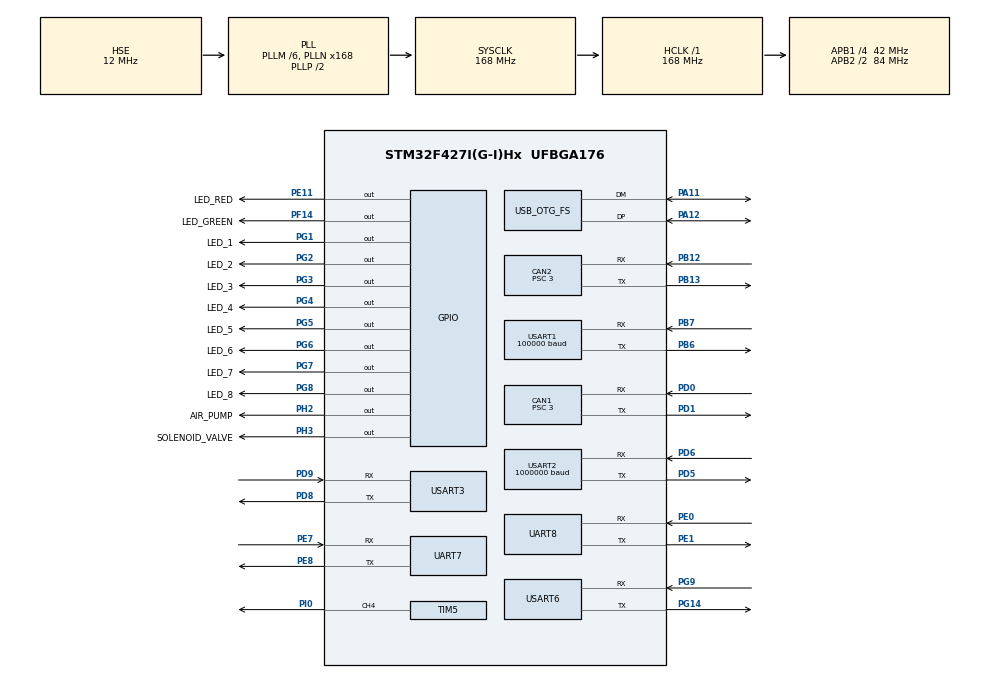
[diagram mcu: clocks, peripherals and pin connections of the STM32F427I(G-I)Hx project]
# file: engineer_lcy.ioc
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CAN1.ABOM=ENABLE
CAN1.BS1=CAN_BS1_7TQ
CAN1.BS2=CAN_BS2_6TQ
CAN1.CalculateBaudRate=1000000
CAN1.CalculateTimeBit=1000
CAN1.CalculateTimeQuantum=71.42857142857143
CAN1.Prescaler=3
CAN2.ABOM=ENABLE
CAN2.BS1=CAN_BS1_7TQ
CAN2.BS2=CAN_BS2_6TQ
CAN2.CalculateBaudRate=1000000
CAN2.CalculateTimeBit=1000
CAN2.CalculateTimeQuantum=71.42857142857143
CAN2.Prescaler=3
Dma.Request0=UART7_RX
Dma.Request1=UART8_RX
Dma.Request2=USART6_RX
Dma.Request3=USART3_RX
Dma.Request4=USART1_RX
Dma.Request5=USART2_RX
Dma.UART7_RX.0.Direction=DMA_PERIPH_TO_MEMORY
Dma.UART7_RX.0.FIFOMode=DMA_FIFOMODE_DISABLE
Dma.UART7_RX.0.Instance=DMA1_Stream3
Dma.UART7_RX.0.MemDataAlignment=DMA_MDATAALIGN_BYTE
Dma.UART7_RX.0.MemInc=DMA_MINC_ENABLE
Dma.UART7_RX.0.Mode=DMA_NORMAL
Dma.UART7_RX.0.PeriphDataAlignment=DMA_PDATAALIGN_BYTE
Dma.UART7_RX.0.PeriphInc=DMA_PINC_DISABLE
Dma.UART7_RX.0.Priority=DMA_PRIORITY_LOW
Dma.UART8_RX.1.Direction=DMA_PERIPH_TO_MEMORY
Dma.UART8_RX.1.FIFOMode=DMA_FIFOMODE_DISABLE
Dma.UART8_RX.1.Instance=DMA1_Stream6
Dma.UART8_RX.1.MemDataAlignment=DMA_MDATAALIGN_BYTE
Dma.UART8_RX.1.MemInc=DMA_MINC_ENABLE
Dma.UART8_RX.1.Mode=DMA_NORMAL
Dma.UART8_RX.1.PeriphDataAlignment=DMA_PDATAALIGN_BYTE
Dma.UART8_RX.1.PeriphInc=DMA_PINC_DISABLE
Dma.UART8_RX.1.Priority=DMA_PRIORITY_LOW
Dma.USART1_RX.4.Direction=DMA_PERIPH_TO_MEMORY
Dma.USART1_RX.4.FIFOMode=DMA_FIFOMODE_DISABLE
Dma.USART1_RX.4.Instance=DMA2_Stream2
Dma.USART1_RX.4.MemDataAlignment=DMA_MDATAALIGN_BYTE
Dma.USART1_RX.4.MemInc=DMA_MINC_ENABLE
Dma.USART1_RX.4.Mode=DMA_NORMAL
Dma.USART1_RX.4.PeriphDataAlignment=DMA_PDATAALIGN_BYTE
Dma.USART1_RX.4.PeriphInc=DMA_PINC_DISABLE
Dma.USART1_RX.4.Priority=DMA_PRIORITY_LOW
Dma.USART2_RX.5.Direction=DMA_PERIPH_TO_MEMORY
Dma.USART2_RX.5.FIFOMode=DMA_FIFOMODE_DISABLE
Dma.USART2_RX.5.Instance=DMA1_Stream5
Dma.USART2_RX.5.MemDataAlignment=DMA_MDATAALIGN_BYTE
Dma.USART2_RX.5.MemInc=DMA_MINC_ENABLE
Dma.USART2_RX.5.Mode=DMA_NORMAL
Dma.USART2_RX.5.PeriphDataAlignment=DMA_PDATAALIGN_BYTE
Dma.USART2_RX.5.PeriphInc=DMA_PINC_DISABLE
Dma.USART2_RX.5.Priority=DMA_PRIORITY_LOW
Dma.USART3_RX.3.Direction=DMA_PERIPH_TO_MEMORY
Dma.USART3_RX.3.FIFOMode=DMA_FIFOMODE_DISABLE
Dma.USART3_RX.3.Instance=DMA1_Stream1
Dma.USART3_RX.3.MemDataAlignment=DMA_MDATAALIGN_BYTE
Dma.USART3_RX.3.MemInc=DMA_MINC_ENABLE
Dma.USART3_RX.3.Mode=DMA_NORMAL
Dma.USART3_RX.3.PeriphDataAlignment=DMA_PDATAALIGN_BYTE
Dma.USART3_RX.3.PeriphInc=DMA_PINC_DISABLE
Dma.USART3_RX.3.Priority=DMA_PRIORITY_LOW
Dma.USART6_RX.2.Direction=DMA_PERIPH_TO_MEMORY
Dma.USART6_RX.2.FIFOMode=DMA_FIFOMODE_DISABLE
Dma.USART6_RX.2.Instance=DMA2_Stream1
Dma.USART6_RX.2.MemDataAlignment=DMA_MDATAALIGN_BYTE
Dma.USART6_RX.2.MemInc=DMA_MINC_ENABLE
Dma.USART6_RX.2.Mode=DMA_NORMAL
Dma.USART6_RX.2.PeriphDataAlignment=DMA_PDATAALIGN_BYTE
Dma.USART6_RX.2.PeriphInc=DMA_PINC_DISABLE
Dma.USART6_RX.2.Priority=DMA_PRIORITY_LOW
IWDG.Prescaler=IWDG_PRESCALER_32
IWDG.Reload=1023
Mcu.Family=STM32F4
Mcu.Name=STM32F427I(G-I)Hx
Mcu.Package=UFBGA176
NVIC.CAN1_RX0_IRQn=true\:0\:0\:false\:false\:true\:true\:true\:true
NVIC.CAN1_RX1_IRQn=true\:0\:0\:false\:false\:true\:true\:true\:true
NVIC.CAN2_RX0_IRQn=true\:0\:0\:false\:false\:true\:true\:true\:true
NVIC.CAN2_RX1_IRQn=true\:0\:0\:false\:false\:true\:true\:true\:true
NVIC.DMA1_Stream1_IRQn=true\:0\:0\:false\:false\:true\:false\:true\:true
NVIC.DMA1_Stream3_IRQn=true\:0\:0\:false\:false\:true\:false\:true\:true
NVIC.DMA1_Stream5_IRQn=true\:0\:0\:false\:false\:true\:false\:true\:true
NVIC.DMA1_Stream6_IRQn=true\:0\:0\:false\:false\:true\:false\:true\:true
NVIC.DMA2_Stream1_IRQn=true\:0\:0\:false\:false\:true\:false\:true\:true
NVIC.DMA2_Stream2_IRQn=true\:0\:0\:false\:false\:true\:false\:true\:true
NVIC.OTG_FS_IRQn=true\:0\:0\:false\:false\:true\:true\:true\:true
NVIC.PriorityGroup=NVIC_PRIORITYGROUP_4
NVIC.TIM6_DAC_IRQn=true\:0\:0\:false\:false\:true\:true\:true\:true
NVIC.UART7_IRQn=true\:0\:0\:false\:false\:true\:true\:true\:true
NVIC.UART8_IRQn=true\:0\:0\:false\:false\:true\:true\:true\:true
NVIC.USART1_IRQn=true\:0\:0\:false\:false\:true\:true\:true\:true
NVIC.USART2_IRQn=true\:0\:0\:false\:false\:true\:true\:true\:true
NVIC.USART3_IRQn=true\:0\:0\:false\:false\:true\:true\:true\:true
NVIC.USART6_IRQn=true\:0\:0\:false\:false\:true\:true\:true\:true
PA11.Mode=Device_Only
PA11.Signal=USB_OTG_FS_DM
PA12.Mode=Device_Only
PA12.Signal=USB_OTG_FS_DP
PA13.Mode=Serial_Wire
PA13.Signal=SYS_JTMS-SWDIO
PA14.Mode=Serial_Wire
PA14.Signal=SYS_JTCK-SWCLK
PB12.Mode=CAN_Activate
PB12.Signal=CAN2_RX
PB13.Mode=CAN_Activate
PB13.Signal=CAN2_TX
PB6.Mode=Asynchronous
PB6.Signal=USART1_TX
PB7.Mode=Asynchronous
PB7.Signal=USART1_RX
PD0.Mode=CAN_Activate
PD0.Signal=CAN1_RX
PD1.Mode=CAN_Activate
PD1.Signal=CAN1_TX
PD5.Mode=Asynchronous
PD5.Signal=USART2_TX
PD6.Mode=Asynchronous
PD6.Signal=USART2_RX
PD8.Mode=Asynchronous
PD8.Signal=USART3_TX
PD9.Mode=Asynchronous
PD9.Signal=USART3_RX
PE0.Mode=Asynchronous
PE0.Signal=UART8_RX
PE1.Mode=Asynchronous
PE1.Signal=UART8_TX
PE11.GPIO_Label=LED_RED
PE11.PinState=GPIO_PIN_SET
PE11.Signal=GPIO_Output
PE7.Mode=Asynchronous
PE7.Signal=UART7_RX
PE8.Mode=Asynchronous
PE8.Signal=UART7_TX
PF14.GPIO_Label=LED_GREEN
PF14.PinState=GPIO_PIN_RESET
PF14.Signal=GPIO_Output
PG1.GPIO_Label=LED_1
PG1.PinState=GPIO_PIN_SET
PG1.Signal=GPIO_Output
PG14.Mode=Asynchronous
PG14.Signal=USART6_TX
PG2.GPIO_Label=LED_2
PG2.PinState=GPIO_PIN_SET
PG2.Signal=GPIO_Output
PG3.GPIO_Label=LED_3
PG3.PinState=GPIO_PIN_SET
PG3.Signal=GPIO_Output
PG4.GPIO_Label=LED_4
PG4.PinState=GPIO_PIN_SET
PG4.Signal=GPIO_Output
PG5.GPIO_Label=LED_5
PG5.PinState=GPIO_PIN_SET
PG5.Signal=GPIO_Output
PG6.GPIO_Label=LED_6
PG6.PinState=GPIO_PIN_SET
PG6.Signal=GPIO_Output
PG7.GPIO_Label=LED_7
PG7.PinState=GPIO_PIN_SET
PG7.Signal=GPIO_Output
PG8.GPIO_Label=LED_8
PG8.PinState=GPIO_PIN_SET
PG8.Signal=GPIO_Output
PG9.Mode=Asynchronous
PG9.Signal=USART6_RX
PH0/OSC_IN.Mode=HSE-External-Oscillator
PH0/OSC_IN.Signal=RCC_OSC_IN
PH1/OSC_OUT.Mode=HSE-External-Oscillator
PH1/OSC_OUT.Signal=RCC_OSC_OUT
PH12.Signal=S_TIM5_CH3
PH2.GPIO_Label=AIR_PUMP
PH2.PinState=GPIO_PIN_RESET
PH2.Signal=GPIO_Output
PH3.GPIO_Label=SOLENOID_VALVE
PH3.PinState=GPIO_PIN_SET
PH3.Signal=GPIO_Output
PI0.Signal=S_TIM5_CH4
ProjectManager.HeapSize=0x200
ProjectManager.StackSize=0x400
ProjectManager.TargetToolchain=STM32CubeIDE
RCC.48MHZClocksFreq_Value=48000000
RCC.AHBFreq_Value=168000000
RCC.APB1CLKDivider=RCC_HCLK_DIV4
RCC.APB1Freq_Value=42000000
RCC.APB1TimFreq_Value=84000000
RCC.APB2CLKDivider=RCC_HCLK_DIV2
RCC.APB2Freq_Value=84000000
RCC.APB2TimFreq_Value=168000000
RCC.CortexFreq_Value=168000000
RCC.HCLKFreq_Value=168000000
RCC.HSE_VALUE=12000000
RCC.HSI_VALUE=16000000
RCC.LSE_VALUE=32768
RCC.PLLM=6
RCC.PLLN=168
RCC.PLLQ=7
RCC.SYSCLKFreq_VALUE=168000000
RCC.SYSCLKSource=RCC_SYSCLKSOURCE_PLLCLK
RCC.VCOOutputFreq_Value=336000000
SH.S_TIM5_CH3.0=TIM5_CH3
SH.S_TIM5_CH4.0=TIM5_CH4,PWM Generation4 CH4
TIM5.Channel-PWM\ Generation4\ CH4=TIM_CHANNEL_4
TIM5.Period=20000-1
TIM5.Prescaler=84-1
TIM6.Period=1000-1
TIM6.Prescaler=84-1
UART7.VirtualMode=Asynchronous
UART8.VirtualMode=Asynchronous
USART1.BaudRate=100000
USART1.Mode=MODE_RX
USART1.Parity=PARITY_EVEN
USART1.VirtualMode=VM_ASYNC
USART1.WordLength=WORDLENGTH_9B
USART2.BaudRate=1000000
USART2.VirtualMode=VM_ASYNC
USART3.VirtualMode=VM_ASYNC
USART6.VirtualMode=VM_ASYNC
USB_DEVICE.CLASS_NAME_FS=CDC
USB_DEVICE.VirtualMode-CDC_FS=Cdc
USB_DEVICE.VirtualModeFS=Cdc_FS
USB_OTG_FS.VirtualMode=Device_Only
VP_IWDG_VS_IWDG.Mode=IWDG_Activate
VP_TIM6_VS_ClockSourceINT.Mode=Enable_Timer
VP_USB_DEVICE_VS_USB_DEVICE_CDC_FS.Mode=CDC_FS
board=custom

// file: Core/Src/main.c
/* USER CODE BEGIN Header */
/**
  ******************************************************************************
  * @file           : main.c
  * @brief          : Main program body
  ******************************************************************************
  * @attention
  *
  * Copyright (c) 2024 STMicroelectronics.
  * All rights reserved.
  *
  * This software is licensed under terms that can be found in the LICENSE file
  * in the root directory of this software component.
  * If no LICENSE file comes with this software, it is provided AS-IS.
  *
  ******************************************************************************
  */
/* USER CODE END Header */
#include "main.h"
#include "can.h"
#include "dma.h"
#include "iwdg.h"
#include "tim.h"
#include "usart.h"
#include "usb_device.h"
#include "gpio.h"

/* USER CODE BEGIN Includes */
#include "User_main.h"
/* USER CODE END Includes */

void SystemClock_Config(void);

int main(void)
{

  /* MCU Configuration--------------------------------------------------------*/

  /* Reset of all peripherals, Initializes the Flash interface and the Systick. */
  HAL_Init();

  /* Configure the system clock */
  SystemClock_Config();

  /* Initialize all configured peripherals */
  MX_GPIO_Init();
  MX_DMA_Init();
  MX_CAN1_Init();
  MX_CAN2_Init();
  MX_USART6_UART_Init();
  MX_TIM6_Init();
  MX_UART7_Init();
  MX_UART8_Init();
  MX_USART3_UART_Init();
  MX_USART1_UART_Init();
  MX_USB_DEVICE_Init();
  MX_TIM5_Init();
  MX_USART2_UART_Init();
  MX_IWDG_Init();
  /* USER CODE BEGIN 2 */
  User_setup();
  /* USER CODE END 2 */

  /* Infinite loop */
  /* USER CODE BEGIN WHILE */
  while (1)
  {
      User_loop();
    /* USER CODE END WHILE */

  }
}

void SystemClock_Config(void)
{
  RCC_OscInitTypeDef RCC_OscInitStruct = {0};
  RCC_ClkInitTypeDef RCC_ClkInitStruct = {0};

  /** Configure the main internal regulator output voltage
  */
  __HAL_RCC_PWR_CLK_ENABLE();
  __HAL_PWR_VOLTAGESCALING_CONFIG(PWR_REGULATOR_VOLTAGE_SCALE1);

  /** Initializes the RCC Oscillators according to the specified parameters
  * in the RCC_OscInitTypeDef structure.
  */
  RCC_OscInitStruct.OscillatorType = RCC_OSCILLATORTYPE_LSI|RCC_OSCILLATORTYPE_HSE;
  RCC_OscInitStruct.HSEState = RCC_HSE_ON;
  RCC_OscInitStruct.LSIState = RCC_LSI_ON;
  RCC_OscInitStruct.PLL.PLLState = RCC_PLL_ON;
  RCC_OscInitStruct.PLL.PLLSource = RCC_PLLSOURCE_HSE;
  RCC_OscInitStruct.PLL.PLLM = 6;
  RCC_OscInitStruct.PLL.PLLN = 168;
  RCC_OscInitStruct.PLL.PLLP = RCC_PLLP_DIV2;
  RCC_OscInitStruct.PLL.PLLQ = 7;
  if (HAL_RCC_OscConfig(&RCC_OscInitStruct) != HAL_OK)
  {
    Error_Handler();
  }

  /** Initializes the CPU, AHB and APB buses clocks
  */
  RCC_ClkInitStruct.ClockType = RCC_CLOCKTYPE_HCLK|RCC_CLOCKTYPE_SYSCLK
                              |RCC_CLOCKTYPE_PCLK1|RCC_CLOCKTYPE_PCLK2;
  RCC_ClkInitStruct.SYSCLKSource = RCC_SYSCLKSOURCE_PLLCLK;
  RCC_ClkInitStruct.AHBCLKDivider = RCC_SYSCLK_DIV1;
  RCC_ClkInitStruct.APB1CLKDivider = RCC_HCLK_DIV4;
  RCC_ClkInitStruct.APB2CLKDivider = RCC_HCLK_DIV2;

  if (HAL_RCC_ClockConfig(&RCC_ClkInitStruct, FLASH_LATENCY_5) != HAL_OK)
  {
    Error_Handler();
  }
}

void Error_Handler(void)
{
  __disable_irq();
  while (1)
  {
  }
}
